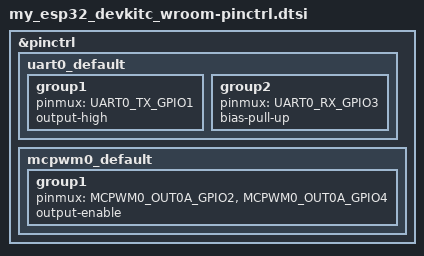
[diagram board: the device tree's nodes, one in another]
/*
 * Copyright (c) 2022 Espressif Systems (Shanghai) Co., Ltd.
 *
 * SPDX-License-Identifier: Apache-2.0
 */

#include <zephyr/dt-bindings/pinctrl/esp-pinctrl-common.h>
#include <dt-bindings/pinctrl/esp32-pinctrl.h>
#include <zephyr/dt-bindings/pinctrl/esp32-gpio-sigmap.h>

&pinctrl {
	uart0_default: uart0_default {
		group1 {
			pinmux = <UART0_TX_GPIO1>;
			output-high;
		};
		group2 {
			pinmux = <UART0_RX_GPIO3>;
			bias-pull-up;
		};
	};

	mcpwm0_default: mcpwm0_default {
		group1 {
			pinmux = <MCPWM0_OUT0A_GPIO2>,
					<MCPWM0_OUT0A_GPIO4>;
			output-enable;
		};
	};
};

